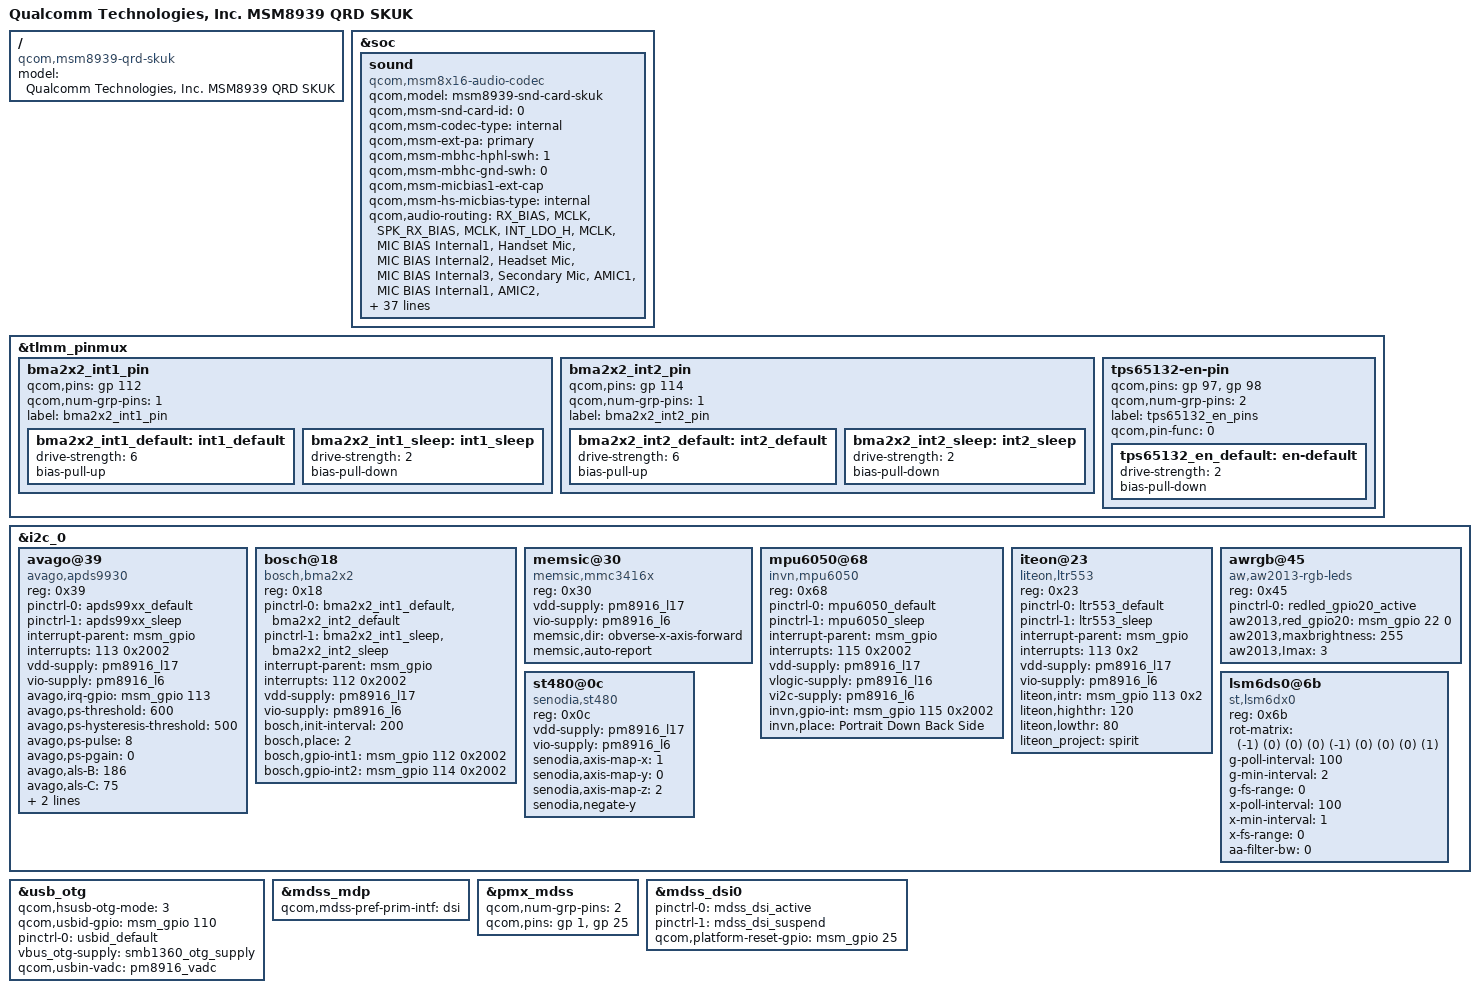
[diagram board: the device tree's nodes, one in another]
/* Copyright (c) 2014, The Linux Foundation. All rights reserved.
 *
 * This program is free software; you can redistribute it and/or modify
 * it under the terms of the GNU General Public License version 2 and
 * only version 2 as published by the Free Software Foundation.
 *
 * This program is distributed in the hope that it will be useful,
 * but WITHOUT ANY WARRANTY; without even the implied warranty of
 * MERCHANTABILITY or FITNESS FOR A PARTICULAR PURPOSE.  See the
 * GNU General Public License for more details.
 */

#include "spirit-msm8939-qrd.dtsi"

/ {
	model = "Qualcomm Technologies, Inc. MSM8939 QRD SKUK";
	compatible = "qcom,msm8939-qrd-skuk", "qcom,msm8939-qrd", "qcom,msm8939", "qcom,qrd";
};

&soc {
	sound {
		compatible = "qcom,msm8x16-audio-codec";
		qcom,model = "msm8939-snd-card-skuk";
		qcom,msm-snd-card-id = <0>;
		qcom,msm-codec-type = "internal";
		qcom,msm-ext-pa = "primary";
		qcom,msm-mbhc-hphl-swh = <1>;
		qcom,msm-mbhc-gnd-swh = <0>;
		qcom,msm-micbias1-ext-cap;
		qcom,msm-hs-micbias-type = "internal";
		qcom,audio-routing =
			"RX_BIAS", "MCLK",
			"SPK_RX_BIAS", "MCLK",
			"INT_LDO_H", "MCLK",
			"MIC BIAS Internal1", "Handset Mic",
			"MIC BIAS Internal2", "Headset Mic",
			"MIC BIAS Internal3", "Secondary Mic",
			"AMIC1", "MIC BIAS Internal1",
			"AMIC2", "MIC BIAS Internal2",
			"AMIC3", "MIC BIAS Internal3";
		pinctrl-names = "cdc_lines_act",
				"cdc_lines_sus";
		pinctrl-0 = <&cdc_pdm_lines_act>;
		pinctrl-1 = <&cdc_pdm_lines_sus>;
		asoc-platform = <&pcm0>, <&pcm1>, <&voip>, <&voice>,
				<&loopback>, <&compress>, <&hostless>,
				<&afe>, <&lsm>, <&routing>, <&lpa>;
		asoc-platform-names = "msm-pcm-dsp.0", "msm-pcm-dsp.1",
				"msm-voip-dsp", "msm-pcm-voice", "msm-pcm-loopback",
				"msm-compress-dsp", "msm-pcm-hostless", "msm-pcm-afe",
				"msm-lsm-client", "msm-pcm-routing", "msm-pcm-lpa";
		asoc-cpu = <&dai_pri_auxpcm>, <&dai_hdmi>, <&dai_mi2s0>, <&dai_mi2s1>,
				<&dai_mi2s2>, <&dai_mi2s3>, <&sb_0_rx>, <&sb_0_tx>,
				<&sb_1_rx>, <&sb_1_tx>, <&sb_3_rx>, <&sb_3_tx>,
				<&sb_4_rx>, <&sb_4_tx>, <&sb_5_tx>, <&bt_sco_rx>,
				<&bt_sco_tx>, <&int_fm_rx>, <&int_fm_tx>, <&afe_pcm_rx>,
				<&afe_pcm_tx>, <&afe_proxy_rx>, <&afe_proxy_tx>,
				<&incall_record_rx>, <&incall_record_tx>, <&incall_music_rx>,
				<&incall_music_2_rx>;
		asoc-cpu-names = "msm-dai-q6-auxpcm.1", "msm-dai-q6-hdmi.8", "msm-dai-q6-mi2s.0",
				"msm-dai-q6-mi2s.1", "msm-dai-q6-mi2s.2",
				"msm-dai-q6-mi2s.3", "msm-dai-q6-dev.16384",
				"msm-dai-q6-dev.16385", "msm-dai-q6-dev.16386",
				"msm-dai-q6-dev.16387", "msm-dai-q6-dev.16390",
				"msm-dai-q6-dev.16391", "msm-dai-q6-dev.16392",
				"msm-dai-q6-dev.16393", "msm-dai-q6-dev.16395",
				"msm-dai-q6-dev.12288", "msm-dai-q6-dev.12289",
				"msm-dai-q6-dev.12292", "msm-dai-q6-dev.12293",
				"msm-dai-q6-dev.224", "msm-dai-q6-dev.225",
				"msm-dai-q6-dev.241", "msm-dai-q6-dev.240",
				"msm-dai-q6-dev.32771", "msm-dai-q6-dev.32772",
				"msm-dai-q6-dev.32773", "msm-dai-q6-dev.32770";
		asoc-codec = <&stub_codec>, <&pm8916_tombak_dig>;
		asoc-codec-names = "msm-stub-codec.1", "tombak_codec";
	};
};

&tlmm_pinmux {
	bma2x2_int1_pin {
		qcom,pins = <&gp 112>;
		qcom,num-grp-pins = <1>;
		label = "bma2x2_int1_pin";
		bma2x2_int1_default: int1_default {
			  drive-strength = <6>;
			  bias-pull-up;
		};
		bma2x2_int1_sleep: int1_sleep {
			  drive-strength = <2>;
			  bias-pull-down;
		};
	};

	bma2x2_int2_pin {
		qcom,pins = <&gp 114>;
		qcom,num-grp-pins = <1>;
		label = "bma2x2_int2_pin";
		bma2x2_int2_default: int2_default {
			  drive-strength = <6>;
			  bias-pull-up;
		};
		bma2x2_int2_sleep: int2_sleep {
			  drive-strength = <2>;
			  bias-pull-down;
		};
	};

	tps65132-en-pin {
		qcom,pins = <&gp 97>, <&gp 98>;
		qcom,num-grp-pins = <2>;
		label = "tps65132_en_pins";
		qcom,pin-func = <0>;

		tps65132_en_default: en-default {
			drive-strength = <2>;
			bias-pull-down;
		};
	};
};

&i2c_0 { /* BLSP1 QUP2 */
	avago@39 { /* Ambient light and proximity sensor */
		compatible = "avago,apds9930";
		reg = <0x39>;
		pinctrl-names = "default","sleep";
		pinctrl-0 = <&apds99xx_default>;
		pinctrl-1 = <&apds99xx_sleep>;
		interrupt-parent = <&msm_gpio>;
		interrupts = <113 0x2002>;
		vdd-supply = <&pm8916_l17>;
		vio-supply = <&pm8916_l6>;
		avago,irq-gpio = <&msm_gpio 113 0x2002>;
		avago,ps-threshold = <600>;
		avago,ps-hysteresis-threshold = <500>;
		avago,ps-pulse = <8>;
		avago,ps-pgain = <0>;
		avago,als-B = <186>;
		avago,als-C = <75>;
		avago,als-D = <129>;
		avago,ga-value = <560>;
	};

	bosch@18 { /* Accelerometer sensor */
		compatible = "bosch,bma2x2";
		reg = <0x18>;
		pinctrl-names = "bma_default","bma_sleep";
		pinctrl-0 = <&bma2x2_int1_default &bma2x2_int2_default>;
		pinctrl-1 = <&bma2x2_int1_sleep &bma2x2_int2_sleep>;
		interrupt-parent = <&msm_gpio>;
		interrupts = <112 0x2002>;
		vdd-supply = <&pm8916_l17>;
		vio-supply = <&pm8916_l6>;
		bosch,init-interval = <200>;
		bosch,place = <2>;
		bosch,gpio-int1 = <&msm_gpio 112 0x2002>;
		bosch,gpio-int2 = <&msm_gpio 114 0x2002>;
	};

	memsic@30 { /* Magnetic field sensor */
		compatible = "memsic,mmc3416x";
		reg = <0x30>;
		vdd-supply = <&pm8916_l17>;
		vio-supply = <&pm8916_l6>;
		memsic,dir = "obverse-x-axis-forward";
		memsic,auto-report;
	};

	mpu6050@68 { /* Gyroscope and accelerometer sensor combo */
		compatible = "invn,mpu6050";
		reg = <0x68>;
		pinctrl-names = "mpu_default","mpu_sleep";
		pinctrl-0 = <&mpu6050_default>;
		pinctrl-1 = <&mpu6050_sleep>;
		interrupt-parent = <&msm_gpio>;
		interrupts = <115 0x2002>;
		vdd-supply = <&pm8916_l17>;
		vlogic-supply = <&pm8916_l16>;
		vi2c-supply = <&pm8916_l6>;
		invn,gpio-int = <&msm_gpio 115 0x2002>;
		invn,place = "Portrait Down Back Side";
	};

	iteon@23 {
		compatible = "liteon,ltr553";
		reg = <0x23>;
		pinctrl-names = "default","sleep";
		pinctrl-0 = <&ltr553_default>;
		pinctrl-1 = <&ltr553_sleep>;
		interrupt-parent = <&msm_gpio>;
		interrupts = <113 0x2>;
		vdd-supply = <&pm8916_l17>;
		vio-supply = <&pm8916_l6>;
		liteon,intr = <&msm_gpio 113 0x2>;
		liteon,highthr = <120>;
		liteon,lowthr = <80>;
		liteon_project = "spirit";
	};

	awrgb@45 {
                   compatible = "aw,aw2013-rgb-leds";
                   reg = <0x45>;
                   pinctrl-names = "redled_gpio";
                   pinctrl-0 =  <&redled_gpio20_active>;
                   aw2013,red_gpio20 = <&msm_gpio 22 0>;
                   aw2013,maxbrightness = <255>;
                   aw2013,Imax = <3>;
       };

	st480@0c {
		compatible = "senodia,st480";
		reg = <0x0c>;
		vdd-supply = <&pm8916_l17>;
		vio-supply = <&pm8916_l6>;
		senodia,axis-map-x = <1>;
		senodia,axis-map-y = <0>;
		senodia,axis-map-z = <2>;
		senodia,negate-y;
	};

	lsm6ds0@6b {
		compatible = "st,lsm6dx0";
		reg = <0x6b>;
		rot-matrix = /bits/ 16 <(-1) (0) (0)
			(0) (-1) (0)
			(0) (0) (1)>;
		g-poll-interval = <100>;
		g-min-interval = <2>;
		g-fs-range = <0>;
		x-poll-interval = <100>;
		x-min-interval = <1>;
		x-fs-range = <0>;
		aa-filter-bw = <0>;
	};
};

/*&sdc2_cd_on {
	/delete-property/ bias-pull-up;
	bias-pull-down;
};

&sdc2_cd_off {
	/delete-property/ bias-disable;
	bias-pull-down;
};*/

/*&sdhc_2 {
	qcom,nonhotplug;
	interrupts = <0 1>;
	interrupt-map = <0 &intc 0 125 0
		1 &intc 0 221 0>;
	interrupt-names = "hc_irq", "pwr_irq";
	/delete-property/ cd-gpios;
};*/

&usb_otg {
       qcom,hsusb-otg-mode = <3>;
       qcom,usbid-gpio = <&msm_gpio 110 0>;
       pinctrl-names = "default";
       pinctrl-0 = <&usbid_default>;
       vbus_otg-supply = <&smb1360_otg_supply>;
       qcom,usbin-vadc = <&pm8916_vadc>;
};

&mdss_mdp {
	qcom,mdss-pref-prim-intf = "dsi";
};

&pmx_mdss {
	qcom,num-grp-pins = <2>;
	qcom,pins = <&gp 1>, <&gp 25>;
};

&mdss_dsi0 {
	pinctrl-names = "mdss_default", "mdss_sleep";
	pinctrl-0 = <&mdss_dsi_active>;
	pinctrl-1 = <&mdss_dsi_suspend>;

	qcom,platform-reset-gpio = <&msm_gpio 25 0>;
};
